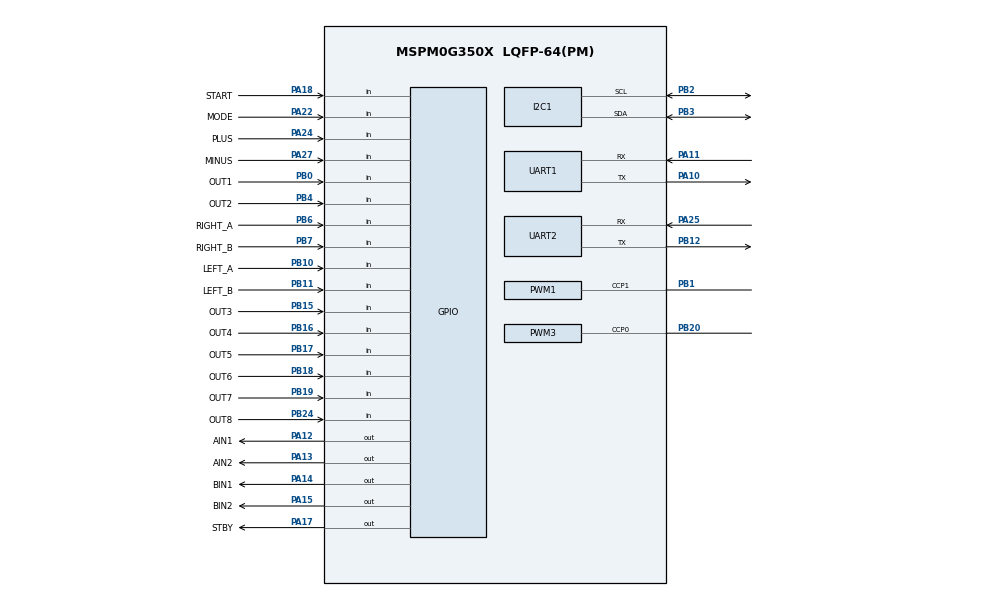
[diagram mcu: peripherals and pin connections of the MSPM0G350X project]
// @v2CliArgs --device "MSPM0G3507" --package "LQFP-64(PM)"
// @cliArgs --device "MSPM0G350X" --package "LQFP-64(PM)" --part "Default" --product "mspm0_sdk@2.10.00.04"
// @versions {"tool":"1.28.0"}

/* H-task competition pin map for the LP-MSPM0G3507 LaunchPad. */
const GPIO    = scripting.addModule("/ti/driverlib/GPIO", {}, false);
const GPIO1   = GPIO.addInstance();
const GPIO3   = GPIO.addInstance();
const GPIO4   = GPIO.addInstance();
const GPIO5   = GPIO.addInstance();
const I2C     = scripting.addModule("/ti/driverlib/I2C", {}, false);
const I2C1    = I2C.addInstance();
const PWM     = scripting.addModule("/ti/driverlib/PWM", {}, false);
const PWM1    = PWM.addInstance();
const PWM2    = PWM.addInstance();
const PWM3    = PWM.addInstance();
const SYSCTL  = scripting.addModule("/ti/driverlib/SYSCTL");
const SYSTICK = scripting.addModule("/ti/driverlib/SYSTICK");
const UART    = scripting.addModule("/ti/driverlib/UART", {}, false);
const UART1   = UART.addInstance();
const UART2   = UART.addInstance();

/* TB6612 motor PWM, matching the proven Test_Trace_plus polarity. */
PWM1.$name                      = "PWM_MOTOR_A";
PWM1.ccIndex                    = [1];
PWM1.enableShadowLoad           = true;
PWM1.clockDivider               = 8;
PWM1.clockPrescale              = 4;
PWM1.timerCount                 = 67;
PWM1.timerStartTimer            = true;
PWM1.peripheral.$assign         = "TIMA1";
PWM1.peripheral.ccp1Pin.$assign = "PB1";
PWM1.ccp1PinConfig.$name        = "ti_driverlib_gpio_PWM_MOTOR_A";
PWM1.PWM_CHANNEL_1.$name        = "ti_driverlib_pwm_TB6612_PWMA";

PWM2.$name                           = "PWM_MOTOR_B";
PWM2.ccIndex                         = [1];
PWM2.ccIndexCmpl                     = [1];
PWM2.enableShadowLoad                = true;
PWM2.clockDivider                    = 8;
PWM2.clockPrescale                   = 4;
PWM2.timerCount                      = 67;
PWM2.timerStartTimer                 = true;
PWM2.peripheral.$assign              = "TIMA0";
PWM2.peripheral.ccp1Pin_cmpl.$assign = "PB13";
PWM2.ccp1PinConfig.$name             = "ti_driverlib_gpio_PWM_MOTOR_B_BASE";
PWM2.ccp1Pin_cmplConfig.$name        = "ti_driverlib_gpio_PWM_MOTOR_B";
PWM2.PWM_CHANNEL_1.$name             = "ti_driverlib_pwm_TB6612_PWMB";
PWM2.peripheral.ccp1Pin.$suggestSolution = "PA1";

/* Final LDX-218 servo: 50 Hz PWM on PB20. */
PWM3.$name                      = "PWM_SERVO";
PWM3.ccIndex                    = [0];
PWM3.clockDivider               = 8;
PWM3.timerCount                 = 80000;
PWM3.timerStartTimer            = true;
PWM3.peripheral.$assign         = "TIMG12";
PWM3.peripheral.ccp0Pin.$assign = "PB20";
PWM3.ccp0PinConfig.$name        = "ti_driverlib_gpio_SERVO_PWM";
PWM3.PWM_CHANNEL_0.$name        = "ti_driverlib_pwm_SERVO_PWM";
PWM3.PWM_CHANNEL_0.dutyCycle    = 7.5;

/* TB6612 direction and standby pins are all on GPIOA. */
GPIO1.$name                          = "MOTOR_GPIOA_OUT";
GPIO1.port                           = "PORTA";
GPIO1.associatedPins.create(5);
GPIO1.associatedPins[0].$name        = "AIN1";
GPIO1.associatedPins[0].assignedPin  = "12";
GPIO1.associatedPins[0].initialValue = "CLEARED";
GPIO1.associatedPins[0].pin.$assign  = "PA12";
GPIO1.associatedPins[1].$name        = "AIN2";
GPIO1.associatedPins[1].assignedPin  = "13";
GPIO1.associatedPins[1].initialValue = "CLEARED";
GPIO1.associatedPins[1].pin.$assign  = "PA13";
GPIO1.associatedPins[2].$name        = "BIN1";
GPIO1.associatedPins[2].assignedPin  = "14";
GPIO1.associatedPins[2].initialValue = "CLEARED";
GPIO1.associatedPins[2].pin.$assign  = "PA14";
GPIO1.associatedPins[3].$name        = "BIN2";
GPIO1.associatedPins[3].assignedPin  = "15";
GPIO1.associatedPins[3].initialValue = "CLEARED";
GPIO1.associatedPins[3].pin.$assign  = "PA15";
GPIO1.associatedPins[4].$name        = "STBY";
GPIO1.associatedPins[4].assignedPin  = "17";
GPIO1.associatedPins[4].initialValue = "CLEARED";
GPIO1.associatedPins[4].pin.$assign  = "PA17";

/* Eight-channel infrared line sensor, OUT1 is the most significant bit. */
GPIO3.$name = "GRAY_GPIOB_IN";
GPIO3.port  = "PORTB";
GPIO3.associatedPins.create(8);
GPIO3.associatedPins[0].$name            = "OUT1";
GPIO3.associatedPins[0].direction        = "INPUT";
GPIO3.associatedPins[0].assignedPin      = "0";
GPIO3.associatedPins[0].internalResistor = "PULL_UP";
GPIO3.associatedPins[0].pin.$assign      = "PB0";
GPIO3.associatedPins[1].$name            = "OUT2";
GPIO3.associatedPins[1].direction        = "INPUT";
GPIO3.associatedPins[1].assignedPin      = "4";
GPIO3.associatedPins[1].internalResistor = "PULL_UP";
GPIO3.associatedPins[1].pin.$assign      = "PB4";
GPIO3.associatedPins[2].$name            = "OUT3";
GPIO3.associatedPins[2].direction        = "INPUT";
GPIO3.associatedPins[2].assignedPin      = "15";
GPIO3.associatedPins[2].internalResistor = "PULL_UP";
GPIO3.associatedPins[2].pin.$assign      = "PB15";
GPIO3.associatedPins[3].$name            = "OUT4";
GPIO3.associatedPins[3].direction        = "INPUT";
GPIO3.associatedPins[3].assignedPin      = "16";
GPIO3.associatedPins[3].internalResistor = "PULL_UP";
GPIO3.associatedPins[3].pin.$assign      = "PB16";
GPIO3.associatedPins[4].$name            = "OUT5";
GPIO3.associatedPins[4].direction        = "INPUT";
GPIO3.associatedPins[4].assignedPin      = "17";
GPIO3.associatedPins[4].internalResistor = "PULL_UP";
GPIO3.associatedPins[4].pin.$assign      = "PB17";
GPIO3.associatedPins[5].$name            = "OUT6";
GPIO3.associatedPins[5].direction        = "INPUT";
GPIO3.associatedPins[5].assignedPin      = "18";
GPIO3.associatedPins[5].internalResistor = "PULL_UP";
GPIO3.associatedPins[5].pin.$assign      = "PB18";
GPIO3.associatedPins[6].$name            = "OUT7";
GPIO3.associatedPins[6].direction        = "INPUT";
GPIO3.associatedPins[6].assignedPin      = "19";
GPIO3.associatedPins[6].internalResistor = "PULL_UP";
GPIO3.associatedPins[6].pin.$assign      = "PB19";
GPIO3.associatedPins[7].$name            = "OUT8";
GPIO3.associatedPins[7].direction        = "INPUT";
GPIO3.associatedPins[7].assignedPin      = "24";
GPIO3.associatedPins[7].internalResistor = "PULL_UP";
GPIO3.associatedPins[7].pin.$assign      = "PB24";

/* Quadrature encoders share the GPIOB GROUP1 interrupt. */
GPIO4.$name = "ENCODER_GPIOB_IN";
GPIO4.port  = "PORTB";
GPIO4.associatedPins.create(4);
GPIO4.associatedPins[0].$name             = "LEFT_A";
GPIO4.associatedPins[0].direction         = "INPUT";
GPIO4.associatedPins[0].assignedPin       = "10";
GPIO4.associatedPins[0].internalResistor  = "PULL_UP";
GPIO4.associatedPins[0].interruptEn       = true;
GPIO4.associatedPins[0].interruptPriority = "1";
GPIO4.associatedPins[0].polarity          = "RISE_FALL";
GPIO4.associatedPins[0].pin.$assign       = "PB10";
GPIO4.associatedPins[1].$name             = "LEFT_B";
GPIO4.associatedPins[1].direction         = "INPUT";
GPIO4.associatedPins[1].assignedPin       = "11";
GPIO4.associatedPins[1].internalResistor  = "PULL_UP";
GPIO4.associatedPins[1].interruptEn       = true;
GPIO4.associatedPins[1].interruptPriority = "1";
GPIO4.associatedPins[1].polarity          = "RISE_FALL";
GPIO4.associatedPins[1].pin.$assign       = "PB11";
GPIO4.associatedPins[2].$name             = "RIGHT_A";
GPIO4.associatedPins[2].direction         = "INPUT";
GPIO4.associatedPins[2].assignedPin       = "6";
GPIO4.associatedPins[2].internalResistor  = "PULL_UP";
GPIO4.associatedPins[2].interruptEn       = true;
GPIO4.associatedPins[2].interruptPriority = "1";
GPIO4.associatedPins[2].polarity          = "RISE_FALL";
GPIO4.associatedPins[2].pin.$assign       = "PB6";
GPIO4.associatedPins[3].$name             = "RIGHT_B";
GPIO4.associatedPins[3].direction         = "INPUT";
GPIO4.associatedPins[3].assignedPin       = "7";
GPIO4.associatedPins[3].internalResistor  = "PULL_UP";
GPIO4.associatedPins[3].interruptEn       = true;
GPIO4.associatedPins[3].interruptPriority = "1";
GPIO4.associatedPins[3].polarity          = "RISE_FALL";
GPIO4.associatedPins[3].pin.$assign       = "PB7";

/* START, MODE, PLUS and MINUS buttons are active low. */
GPIO5.$name = "KEY_GPIOA_IN";
GPIO5.port  = "PORTA";
GPIO5.associatedPins.create(4);
GPIO5.associatedPins[0].$name            = "START";
GPIO5.associatedPins[0].direction        = "INPUT";
GPIO5.associatedPins[0].assignedPin      = "18";
GPIO5.associatedPins[0].internalResistor = "PULL_UP";
GPIO5.associatedPins[0].pin.$assign      = "PA18";
GPIO5.associatedPins[1].$name            = "MODE";
GPIO5.associatedPins[1].direction        = "INPUT";
GPIO5.associatedPins[1].assignedPin      = "22";
GPIO5.associatedPins[1].internalResistor = "PULL_UP";
GPIO5.associatedPins[1].pin.$assign      = "PA22";
GPIO5.associatedPins[2].$name            = "PLUS";
GPIO5.associatedPins[2].direction        = "INPUT";
GPIO5.associatedPins[2].assignedPin      = "24";
GPIO5.associatedPins[2].internalResistor = "PULL_UP";
GPIO5.associatedPins[2].pin.$assign      = "PA24";
GPIO5.associatedPins[3].$name            = "MINUS";
GPIO5.associatedPins[3].direction        = "INPUT";
GPIO5.associatedPins[3].assignedPin      = "27";
GPIO5.associatedPins[3].internalResistor = "PULL_UP";
GPIO5.associatedPins[3].pin.$assign      = "PA27";

/* OLED: I2C1 on PB2/PB3. */
I2C1.$name                     = "I2C_OLED";
I2C1.basicEnableController     = true;
I2C1.basicControllerBusSpeed   = 400000;
I2C1.advAnalogGlitchFilter     = "DISABLED";
I2C1.peripheral.$assign        = "I2C1";
I2C1.peripheral.sclPin.$assign = "PB2";
I2C1.peripheral.sdaPin.$assign = "PB3";

SYSCTL.forceDefaultClkConfig = true;

SYSTICK.period          = 32000;
SYSTICK.periodEnable    = true;
SYSTICK.systickEnable   = true;
SYSTICK.interruptEnable = true;

/* USB backchannel debug UART. */
UART1.$name                    = "UART_0";
UART1.targetBaudRate           = 115200;
UART1.enabledInterrupts        = ["RX"];
UART1.peripheral.$assign       = "UART0";
UART1.peripheral.rxPin.$assign = "PA11";
UART1.peripheral.txPin.$assign = "PA10";
UART1.txPinConfig.$name        = "ti_driverlib_gpio_UART0_TX";
UART1.rxPinConfig.$name        = "ti_driverlib_gpio_UART0_RX";

/* K230: G3507 PB12 TX -> K230 RX, PA25 RX <- K230 TX. */
UART2.$name                    = "UART_K230";
UART2.targetBaudRate           = 115200;
UART2.enabledInterrupts        = ["RX"];
UART2.peripheral.$assign       = "UART3";
UART2.peripheral.rxPin.$assign = "PA25";
UART2.peripheral.txPin.$assign = "PB12";
UART2.txPinConfig.$name        = "ti_driverlib_gpio_K230_TX";
UART2.rxPinConfig.$name        = "ti_driverlib_gpio_K230_RX";

const Board = scripting.addModule("/ti/driverlib/Board", {}, false);
Board.peripheral.$suggestSolution          = "DEBUGSS";
Board.peripheral.swclkPin.$suggestSolution = "PA20";
Board.peripheral.swdioPin.$suggestSolution = "PA19";
SYSCTL.peripheral.$suggestSolution         = "SYSCTL";
